# DA14531 register map
Vendor: Dialog; Series: DA14531; File version: 1.2
CPU: CM0 r1p0, little endian, MPU, FPU, 3 interrupt priority bits
Registers are 16-bit, read-write, reset 0x0 unless marked. A register's access mark holds for its fields unless they carry their own. Offsets are from the block's base; [hi:lo] are bit positions; {n}, {i} and the like mark numbered series; 'fields as' and 'values as' point back to an identical list.

## GPIO — GPIO registers
Base 0x50003000
0x00 P0_DATA_REG — P0 Data input/output Register
  [11:0] P0_DATA — Sets P0 output register when written ; Returns the value of P0 port when read
0x02 P0_SET_DATA_REG — P0 Set port pins Register
  [11:0] P0_SET wo — Writing a 1 to P0[x] sets P0[x] to 1. Writing 0 is discarded, reading returns 0
0x04 P0_RESET_DATA_REG — P0 Reset port pins Register
  [11:0] P0_RESET wo — Writing a 1 to P0[x] sets P0[x] to 0. Writing 0 is discarded, reading returns 0.
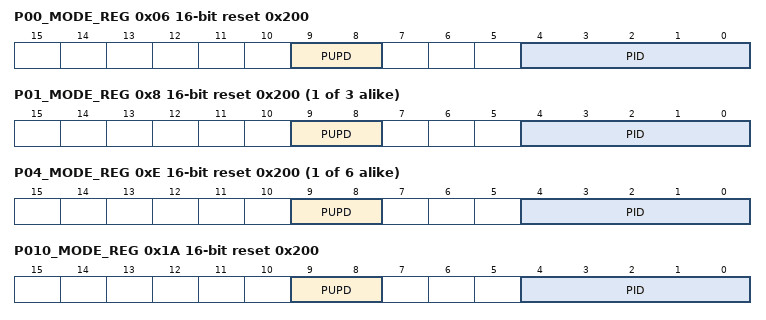
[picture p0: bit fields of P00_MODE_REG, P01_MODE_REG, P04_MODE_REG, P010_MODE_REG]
0x06 P00_MODE_REG reset 0x200 — P00 Mode Register
  [9:8] PUPD — 00 = Input, no resistors selected 01 = Input, pull-up selected 10 = Input, pull-down selected 11 = Output, no resistors selected In ADC mode, these bits are don't care
  [4:0] PID — Function of port 0 = GPIO (pin direction determined by "PUPD" field) 1 = UART1_RX 2 = UART1_TX 3 = UART2_RX 4 = UART2_TX 5 = SYS_CLK 6 = LP_CLK 7 = Reserved 8 = Reserved 9 = I2C_SCL 10 = I2C_SDA 11 = PWM5 12 = PWM6 13 = PWM7 14 = Reserved 15 = ADC (only for P0_1, P0_2, P0_6 and P0_7) 16 = PWM0 17 = PWM1 18 = BLE_DIAG (signals mapped to P0[3:0] are also mapped to P0[11:8]) 19 = UART1_CTSN 20 = UART1_RTSN 21 = Reserved 22 = Reserved 23 = PWM2 24 = PWM3 25 = PWM4 26 = SPI_DI 27 = SPI_DO 28 = SPI_CLK 29 = SPI_CSN0 30 = SPI_CSN1 31 = Reserved Note: When a certain input function (like SPI_DI) is selected on more than 1 pins, the pin of the lowest index has the highest priority.
{0x6+2i} P{i:02}_MODE_REG reset 0x200 (i=1..3) — P{i:02} Mode Register
  [9:8] PUPD — 00 = Input, no resistors selected 01 = Input, pull-up selected 10 = Input, pull-down selected 11 = Output, no resistors selected In ADC mode, these bits are don't care
  [4:0] PID — See P00_MODE_REG[PID]
{0x6+2i} P{i:02}_MODE_REG reset 0x200 (i=4..9) — P{i:02} Mode Register
  [9:8] PUPD — 00 = Input, no resistors selected 01 = Input, pull-up selected 10 = Input, pull-down selected 11 = Output, no resistors selected
  [4:0] PID — See P00_MODE_REG[PID]
0x1A P010_MODE_REG reset 0x200 — P010 Mode Register
  fields as P04_MODE_REG
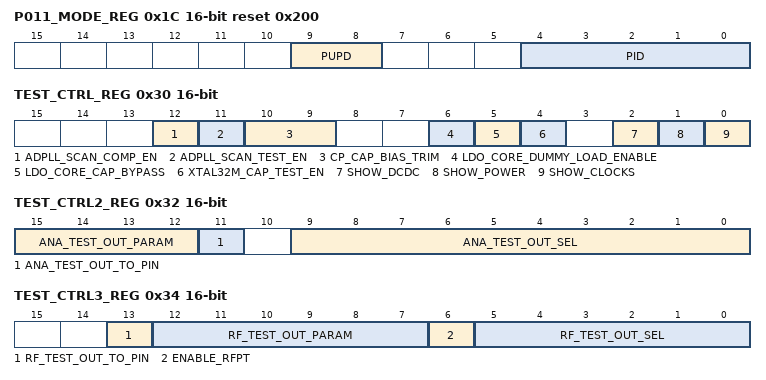
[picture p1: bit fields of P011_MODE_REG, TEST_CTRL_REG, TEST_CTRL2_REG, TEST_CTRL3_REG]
0x1C P011_MODE_REG reset 0x200 — P011 Mode Register
  fields as P04_MODE_REG
0x1E PAD_WEAK_CTRL_REG — Pad driving strength control Register
  [11:0] PAD_LOW_DRV — 0 = Normal operation 1 = Reduces the driving strength of P0_x pad. Bit x controls the driving strength of P0_x, x=0, 1,..., 11.
0x20 SCAN_OBSERVE_REG
  [15:0] SCAN_FEEDBACK_MUX ro
0x30 TEST_CTRL_REG
  [12] ADPLL_SCAN_COMP_EN, [11] ADPLL_SCAN_TEST_EN, [10:9] CP_CAP_BIAS_TRIM, [6] LDO_CORE_DUMMY_LOAD_ENABLE, [5] LDO_CORE_CAP_BYPASS, [4] XTAL32M_CAP_TEST_EN, [2] SHOW_DCDC, [1] SHOW_POWER, [0] SHOW_CLOCKS
0x32 TEST_CTRL2_REG
  [15:12] ANA_TEST_OUT_PARAM, [11] ANA_TEST_OUT_TO_PIN, [9:0] ANA_TEST_OUT_SEL
0x34 TEST_CTRL3_REG
  [13] RF_TEST_OUT_TO_PIN, [12:7] RF_TEST_OUT_PARAM, [6] ENABLE_RFPT, [5:0] RF_TEST_OUT_SEL
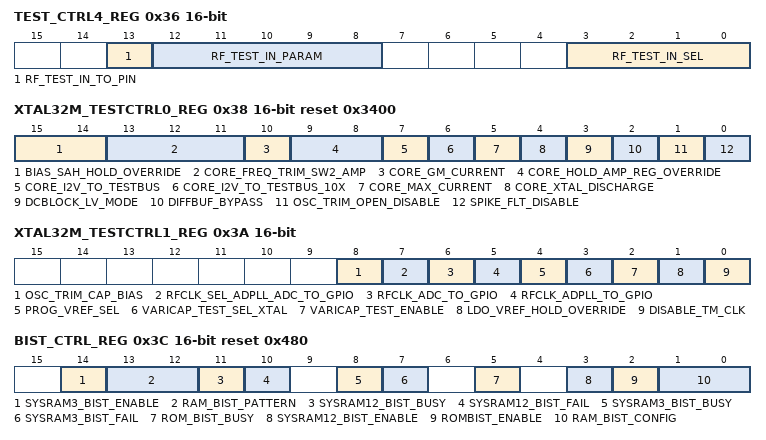
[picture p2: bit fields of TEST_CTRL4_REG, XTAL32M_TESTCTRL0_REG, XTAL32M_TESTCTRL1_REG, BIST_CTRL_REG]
0x36 TEST_CTRL4_REG
  [13] RF_TEST_IN_TO_PIN, [12:8] RF_TEST_IN_PARAM, [3:0] RF_TEST_IN_SEL
0x38 XTAL32M_TESTCTRL0_REG reset 0x3400
  [15:14] BIAS_SAH_HOLD_OVERRIDE, [13:11] CORE_FREQ_TRIM_SW2_AMP, [10] CORE_GM_CURRENT, [9:8] CORE_HOLD_AMP_REG_OVERRIDE, [7] CORE_I2V_TO_TESTBUS, [6] CORE_I2V_TO_TESTBUS_10X, [5] CORE_MAX_CURRENT, [4] CORE_XTAL_DISCHARGE, [3] DCBLOCK_LV_MODE, [2] DIFFBUF_BYPASS, [1] OSC_TRIM_OPEN_DISABLE, [0] SPIKE_FLT_DISABLE
0x3A XTAL32M_TESTCTRL1_REG
  [8] OSC_TRIM_CAP_BIAS, [7] RFCLK_SEL_ADPLL_ADC_TO_GPIO, [6] RFCLK_ADC_TO_GPIO, [5] RFCLK_ADPLL_TO_GPIO, [4] PROG_VREF_SEL, [3] VARICAP_TEST_SEL_XTAL, [2] VARICAP_TEST_ENABLE, [1] LDO_VREF_HOLD_OVERRIDE, [0] DISABLE_TM_CLK
0x3C BIST_CTRL_REG reset 0x480
  [14] SYSRAM3_BIST_ENABLE, [13:12] RAM_BIST_PATTERN, [11] SYSRAM12_BIST_BUSY ro, [10] SYSRAM12_BIST_FAIL ro, [8] SYSRAM3_BIST_BUSY ro, [7] SYSRAM3_BIST_FAIL ro, [5] ROM_BIST_BUSY ro, [3] SYSRAM12_BIST_ENABLE, [2] ROMBIST_ENABLE, [1:0] RAM_BIST_CONFIG
0x3E ROMBIST_RESULTL_REG
  [15:0] ROMBIST_RESULTL ro
0x40 ROMBIST_RESULTH_REG
  [15:0] ROMBIST_RESULTH ro
